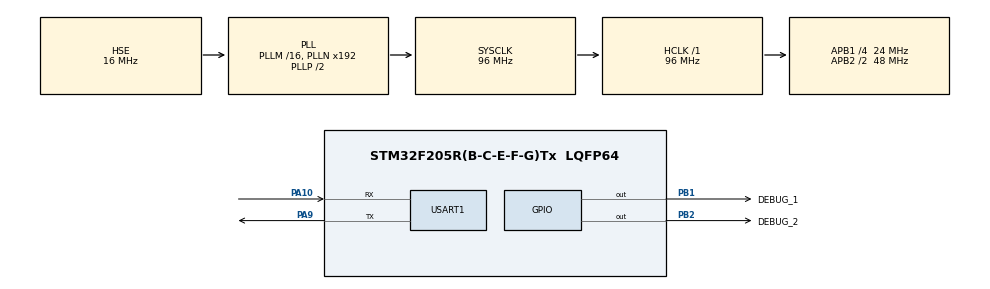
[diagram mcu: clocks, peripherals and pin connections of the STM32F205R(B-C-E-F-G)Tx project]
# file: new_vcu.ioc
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Mcu.Family=STM32F2
Mcu.Name=STM32F205R(B-C-E-F-G)Tx
Mcu.Package=LQFP64
NVIC.PriorityGroup=NVIC_PRIORITYGROUP_4
PA10.Mode=Asynchronous
PA10.Signal=USART1_RX
PA9.Mode=Asynchronous
PA9.Signal=USART1_TX
PB1.GPIO_Label=DEBUG_1
PB1.Signal=GPIO_Output
PB2.GPIO_Label=DEBUG_2
PB2.Signal=GPIO_Output
PH0-OSC_IN.Mode=HSE-External-Oscillator
PH0-OSC_IN.Signal=RCC_OSC_IN
PH1-OSC_OUT.Mode=HSE-External-Oscillator
PH1-OSC_OUT.Signal=RCC_OSC_OUT
ProjectManager.HeapSize=0x200
ProjectManager.StackSize=0x400
ProjectManager.TargetToolchain=Makefile
RCC.48MHZClocksFreq_Value=48000000
RCC.AHBFreq_Value=96000000
RCC.APB1CLKDivider=RCC_HCLK_DIV4
RCC.APB1Freq_Value=24000000
RCC.APB1TimFreq_Value=48000000
RCC.APB2CLKDivider=RCC_HCLK_DIV2
RCC.APB2Freq_Value=48000000
RCC.APB2TimFreq_Value=96000000
RCC.CortexFreq_Value=96000000
RCC.HCLKFreq_Value=96000000
RCC.HSE_VALUE=16000000
RCC.HSI_VALUE=16000000
RCC.PLLSourceVirtual=RCC_PLLSOURCE_HSE
RCC.SYSCLKFreq_VALUE=96000000
RCC.SYSCLKSource=RCC_SYSCLKSOURCE_PLLCLK
RCC.VCOOutputFreq_Value=192000000
USART1.VirtualMode=VM_ASYNC
board=custom

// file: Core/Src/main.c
/* USER CODE BEGIN Header */
/**
 ******************************************************************************
 * @file           : main.c
 * @brief          : Main program body
 ******************************************************************************
 * @attention
 *
 * Copyright (c) 2025 STMicroelectronics.
 * All rights reserved.
 *
 * This software is licensed under terms that can be found in the LICENSE file
 * in the root directory of this software component.
 * If no LICENSE file comes with this software, it is provided AS-IS.
 *
 ******************************************************************************
 */
/* USER CODE END Header */
#include "main.h"
#include "gpio.h"
#include "usart.h"

/* USER CODE BEGIN Includes */
#include <stdio.h>
/* USER CODE END Includes */

/* USER CODE BEGIN PD */
#define PUTCHAR_PROTOTYPE int __io_putchar(int ch)
/* USER CODE END PD */

void SystemClock_Config(void);

int main(void) {

  /* MCU Configuration--------------------------------------------------------*/

  /* Reset of all peripherals, Initializes the Flash interface and the Systick.
   */
  HAL_Init();

  /* Configure the system clock */
  SystemClock_Config();

  /* Initialize all configured peripherals */
  MX_GPIO_Init();
  MX_USART1_UART_Init();
  /* USER CODE BEGIN 2 */
  HAL_GPIO_WritePin(DEBUG_1_GPIO_Port, DEBUG_1_Pin, GPIO_PIN_SET);
  uint32_t toggle_count = 0;
  /* USER CODE END 2 */

  /* Infinite loop */
  /* USER CODE BEGIN WHILE */
  while (1) {
    HAL_GPIO_TogglePin(DEBUG_1_GPIO_Port, DEBUG_1_Pin);
    HAL_GPIO_TogglePin(DEBUG_2_GPIO_Port, DEBUG_2_Pin);
    printf("Hello! The LED has toggled: %li times.\r\n", toggle_count);
    HAL_Delay(500);
    /* USER CODE END WHILE */

  }
}

void SystemClock_Config(void) {
  RCC_OscInitTypeDef RCC_OscInitStruct = {0};
  RCC_ClkInitTypeDef RCC_ClkInitStruct = {0};

  /** Initializes the RCC Oscillators according to the specified parameters
   * in the RCC_OscInitTypeDef structure.
   */
  RCC_OscInitStruct.OscillatorType = RCC_OSCILLATORTYPE_HSE;
  RCC_OscInitStruct.HSEState = RCC_HSE_ON;
  RCC_OscInitStruct.PLL.PLLState = RCC_PLL_ON;
  RCC_OscInitStruct.PLL.PLLSource = RCC_PLLSOURCE_HSE;
  RCC_OscInitStruct.PLL.PLLM = 16;
  RCC_OscInitStruct.PLL.PLLN = 192;
  RCC_OscInitStruct.PLL.PLLP = RCC_PLLP_DIV2;
  RCC_OscInitStruct.PLL.PLLQ = 4;
  if (HAL_RCC_OscConfig(&RCC_OscInitStruct) != HAL_OK) {
    Error_Handler();
  }

  /** Initializes the CPU, AHB and APB buses clocks
   */
  RCC_ClkInitStruct.ClockType = RCC_CLOCKTYPE_HCLK | RCC_CLOCKTYPE_SYSCLK |
                                RCC_CLOCKTYPE_PCLK1 | RCC_CLOCKTYPE_PCLK2;
  RCC_ClkInitStruct.SYSCLKSource = RCC_SYSCLKSOURCE_PLLCLK;
  RCC_ClkInitStruct.AHBCLKDivider = RCC_SYSCLK_DIV1;
  RCC_ClkInitStruct.APB1CLKDivider = RCC_HCLK_DIV4;
  RCC_ClkInitStruct.APB2CLKDivider = RCC_HCLK_DIV2;

  if (HAL_RCC_ClockConfig(&RCC_ClkInitStruct, FLASH_LATENCY_3) != HAL_OK) {
    Error_Handler();
  }
}

/* USER CODE BEGIN 4 */
/**
 * @brief  Retargets the C library printf function to the USART.
 * @retval None
 */
PUTCHAR_PROTOTYPE {
  /* Place your implementation of fputc here */
  /* e.g. write a character to the USART1 and Loop until the end of transmission
   */
  HAL_UART_Transmit(&huart1, (uint8_t *)&ch, 1, 0xFFFF);

  return ch;
}
/* USER CODE END 4 */

void Error_Handler(void) {
  __disable_irq();
  while (1) {
  }
}

#ifdef USE_FULL_ASSERT
/**
 * @brief  Reports the name of the source file and the source line number
 *         where the assert_param error has occurred.
 * @param  file: pointer to the source file name
 * @param  line: assert_param error line source number
 * @retval None
 */
void assert_failed(uint8_t *file, uint32_t line) {
  /* USER CODE BEGIN 6 */
  /* User can add his own implementation to report the file name and line
     number, ex: printf("Wrong parameters value: file %s on line %d\r\n", file,
     line) */
  /* USER CODE END 6 */
}
#endif /* USE_FULL_ASSERT */
